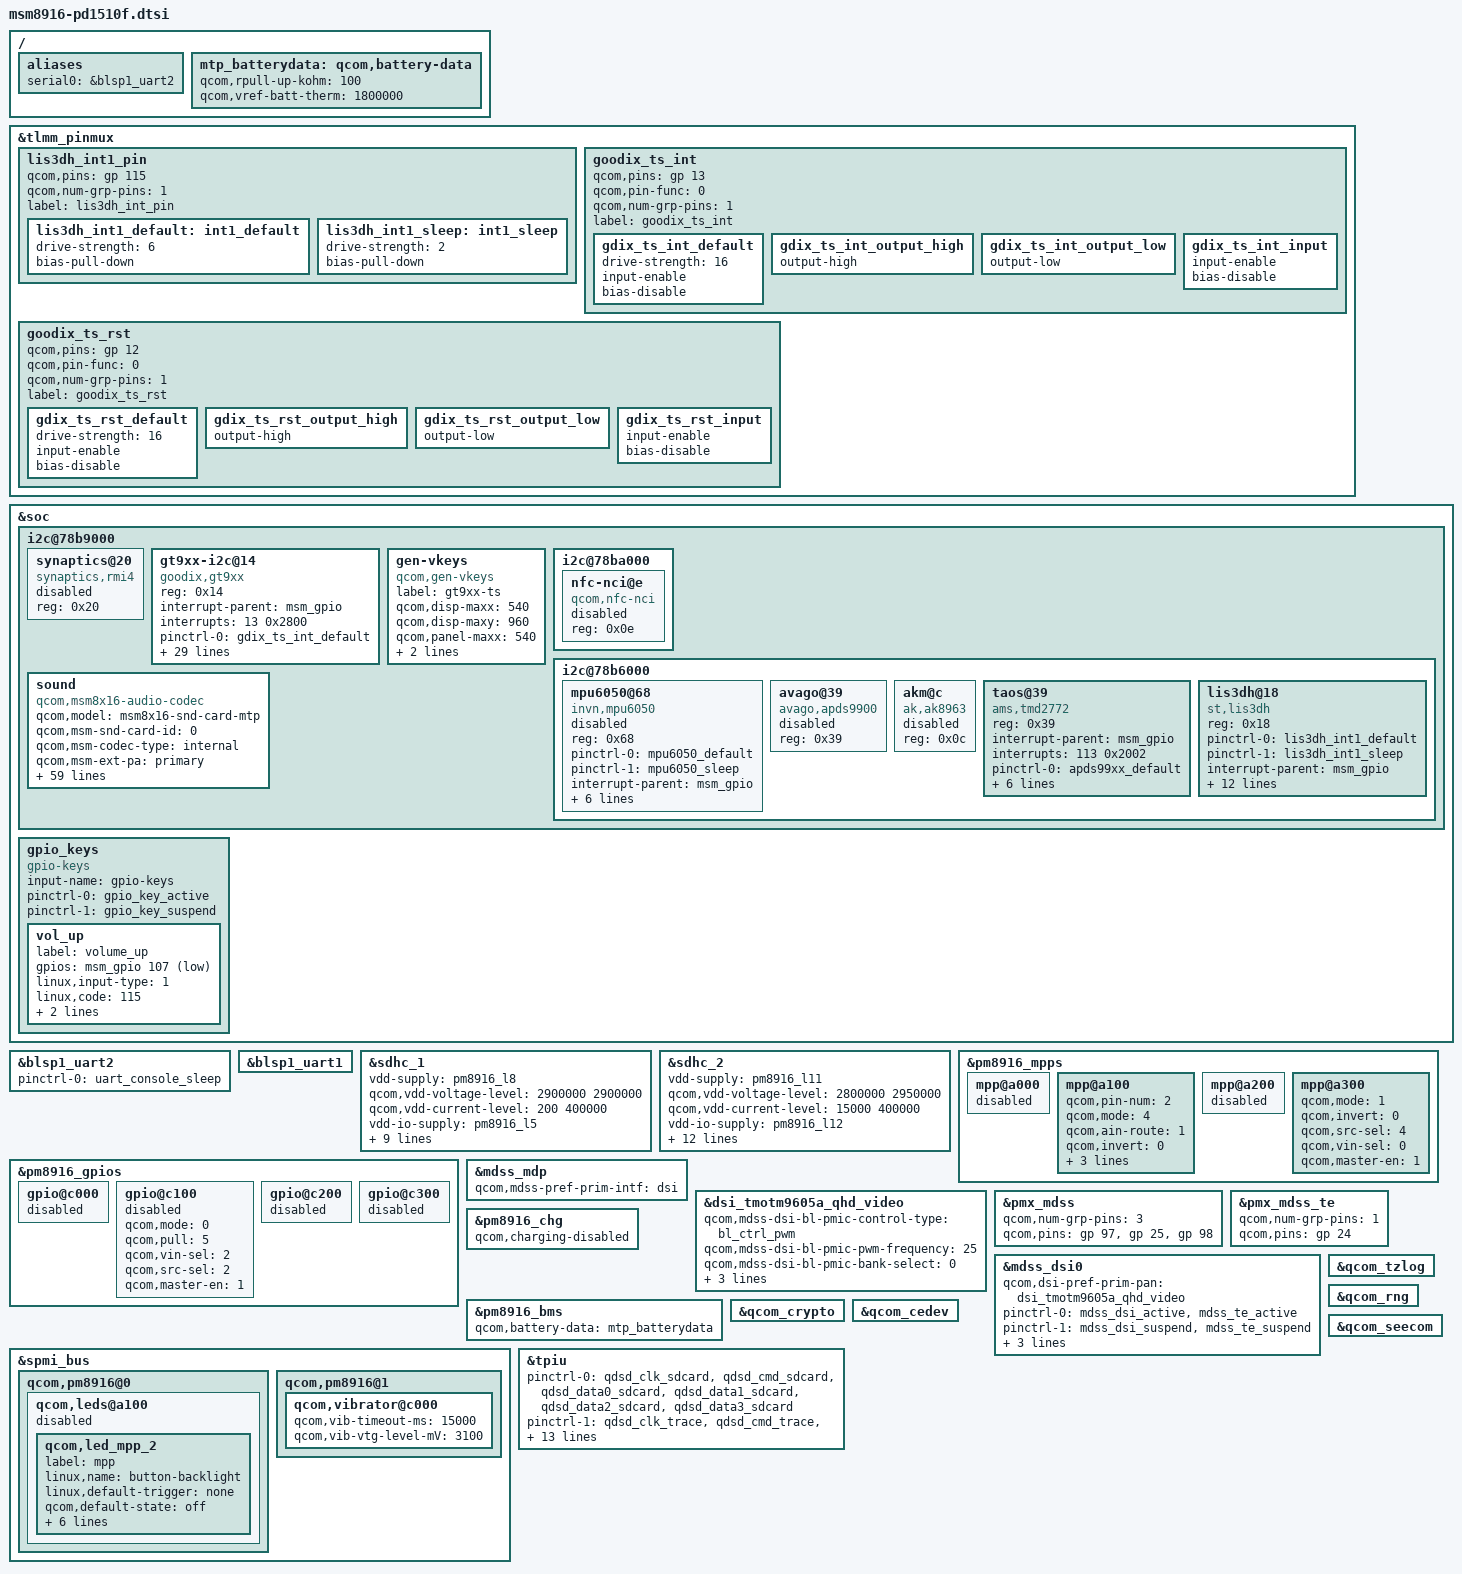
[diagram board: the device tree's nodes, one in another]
/* Copyright (c) 2020, The Linux Foundation. All rights reserved.
 *
 * This program is free software; you can redistribute it and/or modify
 * it under the terms of the GNU General Public License version 2 and
 * only version 2 as published by the Free Software Foundation.
 *
 * This program is distributed in the hope that it will be useful,
 * but WITHOUT ANY WARRANTY; without even the implied warranty of
 * MERCHANTABILITY or FITNESS FOR A PARTICULAR PURPOSE.  See the
 * GNU General Public License for more details.
 */

#include "msm8916.dtsi"
#include "msm8916-pinctrl.dtsi"
#include "msm8916-camera-pd1510f.dtsi"

/ {
	aliases {
		serial0 = &blsp1_uart2;
	};
};

&tlmm_pinmux {
	lis3dh_int1_pin {
		qcom,pins = <&gp 115>;
		qcom,num-grp-pins = <1>;
		label = "lis3dh_int_pin";

		lis3dh_int1_default: int1_default {
				drive-strength = <6>;
				bias-pull-down;
		};

		lis3dh_int1_sleep: int1_sleep {
				drive-strength = <2>;
				bias-pull-down;
		};
	};

	goodix_ts_int {
		qcom,pins = <&gp 13>;
		qcom,pin-func = <0>;
		qcom,num-grp-pins = <1>;
		label = "goodix_ts_int";

		gdix_ts_int_default: gdix_ts_int_default {
			drive-strength = <16>;
			input-enable;
			bias-disable;
		};

		gdix_ts_int_output_high: gdix_ts_int_output_high {
			output-high;
		};

		gdix_ts_int_output_low: gdix_ts_int_output_low {
			output-low;
		};

		gdix_ts_int_input: gdix_ts_int_input {
			input-enable;
			bias-disable;
		};
	};

	goodix_ts_rst {
		qcom,pins = <&gp 12>;
		qcom,pin-func = <0>;
		qcom,num-grp-pins = <1>;
		label = "goodix_ts_rst";

		gdix_ts_rst_default: gdix_ts_rst_default {
			drive-strength = <16>;
			input-enable;
			bias-disable;
		};

		gdix_ts_rst_output_high: gdix_ts_rst_output_high {
			output-high;
		};

		gdix_ts_rst_output_low: gdix_ts_rst_output_low {
			output-low;
		};

		gdix_ts_rst_input: gdix_ts_rst_input {
			input-enable;
			bias-disable;
		};
	};

};

&soc {
	i2c@78b9000 { /* BLSP1 QUP5 */
		synaptics@20 {
			compatible = "synaptics,rmi4";
			reg = <0x20>;
			status = "disabled";
	};

	gt9xx-i2c@14 {
			compatible = "goodix,gt9xx";
			reg = <0x14>;
			interrupt-parent = <&msm_gpio>;
			interrupts = <13 0x2800>;
			pinctrl-names = "gdix_ts_int_default",
				"gdix_ts_int_output_low",
				"gdix_ts_int_output_high",
				"gdix_ts_int_input",
				"gdix_ts_rst_default",
				"gdix_ts_rst_output_low",
				"gdix_ts_rst_output_high",
				"gdix_ts_rst_input";
			pinctrl-0 = <&gdix_ts_int_default>;
			pinctrl-1 = <&gdix_ts_int_output_low>;
			pinctrl-2 = <&gdix_ts_int_output_high>;
			pinctrl-3 = <&gdix_ts_int_input>;
			pinctrl-4 = <&gdix_ts_rst_default>;
			pinctrl-5 = <&gdix_ts_rst_output_low>;
			pinctrl-6 = <&gdix_ts_rst_output_high>;
			pinctrl-7 = <&gdix_ts_rst_input>;
			reset-gpios = <&msm_gpio 12 0x00>;
			irq-gpios = <&msm_gpio 13 0x2800>;
			irq-flags = <1>;
			vdd_ana-supply = <&pm8916_l16>;
			vcc_i2c-supply = <&pm8916_l6>;
			touchscreen-max-id = <11>;
			touchscreen-size-x = <540>;
			touchscreen-size-y = <960>;
			touchscreen-max-w = <512>;
			touchscreen-max-p = <512>;
			touchscreen-key-map = <158>, <102>, <139>; /*KEY_BACK=158，KEY_HOMEPAGE=102, KEY_MENU=139*/
			goodix,slide-wakeup = <1>;
			goodix,type-a-report = <0>;
			goodix,driver-send-cfg = <1>;
			goodix,resume-in-workqueue = <0>;
			goodix,int-sync = <1>;
			goodix,swap-x2y = <0>;
			goodix,esd-protect = <1>;
			goodix,auto-update = <0>;
			goodix,auto-update-cfg = <0>;
			goodix,power-off-sleep = <0>;
			goodix,pen-suppress-finger = <0>;
		};

	gen-vkeys {
		compatible = "qcom,gen-vkeys";
		label = "gt9xx-ts";
		qcom,disp-maxx = <540>;
		qcom,disp-maxy = <960>;
		qcom,panel-maxx = <540>;
		qcom,panel-maxy = <1030>;
		qcom,key-codes = <158 102 139>;
	};

	i2c@78ba000 { /* BLSP1 QUP6 */
		nfc-nci@e {
			compatible = "qcom,nfc-nci";
			reg = <0x0e>;
			status = "disabled";
		};
	};

	i2c@78b6000 { /* BLSP1 QUP2 */
		mpu6050@68 { /* Gyroscope and accelerometer sensor combo */
			compatible = "invn,mpu6050";
			reg = <0x68>;
			status = "disabled";
			pinctrl-names = "mpu_default","mpu_sleep";
			pinctrl-0 = <&mpu6050_default>;
			pinctrl-1 = <&mpu6050_sleep>;
			interrupt-parent = <&msm_gpio>;
			interrupts = <115 0x2>;
			vdd-supply = <&pm8916_l17>;
			vlogic-supply = <&pm8916_l16>;
			vi2c-supply = <&pm8916_l6>;
			invn,gpio-int = <&msm_gpio 115 0x2>;
			invn,place = "Portrait Down Back Side";
		};

		avago@39 { /* Ambient light and proximity sensor */
			compatible = "avago,apds9900";
			reg = <0x39>;
			status = "disabled";
		};

		akm@c {
			compatible = "ak,ak8963";
			reg = <0x0c>;
			status = "disabled";
		};

		taos@39 {
			compatible = "ams,tmd2772";
			reg = <0x39>;
			interrupt-parent = <&msm_gpio>;
			interrupts = <113 0x2002>;
			pinctrl-names = "tmd2772_default","tmd2772_sleep";
			pinctrl-0 = <&apds99xx_default>;
			pinctrl-1 = <&apds99xx_sleep>;
			vdd-supply = <&pm8916_l17>;
			vio-supply = <&pm8916_l6>;
			ams,irq-gpio = <&msm_gpio 113 0x2002>;
			ams,pul_cnt = <12>;
			ams,light-percent = <150>;
		};

		lis3dh@18 {
			compatible = "st,lis3dh";
			reg = <0x18>;
			pinctrl-names = "lis3dh_default","lis3dh_sleep";
			pinctrl-0 = <&lis3dh_int1_default>;
			pinctrl-1 = <&lis3dh_int1_sleep>;
			interrupt-parent = <&msm_gpio>;
			vdd-supply = <&pm8916_l17>;
			vddio-supply = <&pm8916_l6>;
			st,min-interval = <10>;
			st,init-interval = <200>;
			st,axis-map-x = <1>;
			st,axis-map-y = <0>;
			st,axis-map-z = <2>;
			st,g-range = <2>;
			st,gpio-int1 = <&msm_gpio 115 0x2002>;
			st,negate-x = <0>;
			st,negate-y = <0>;
			st,negate-z = <0>;
		};

	};

	sound {
		compatible = "qcom,msm8x16-audio-codec";
		qcom,model = "msm8x16-snd-card-mtp";
		qcom,msm-snd-card-id = <0>;
		qcom,msm-codec-type = "internal";
		qcom,msm-ext-pa = "primary";
		qcom,msm-mclk-freq = <9600000>;
		qcom,msm-mbhc-hphl-swh = <0>;
		qcom,msm-mbhc-gnd-swh = <0>;
		qcom,msm-micbias1-ext-cap;
		qcom,msm-hs-micbias-type = "external";
		qcom,audio-routing =
			"RX_BIAS", "MCLK",
			"SPK_RX_BIAS", "MCLK",
			"INT_LDO_H", "MCLK",
			"MIC BIAS External", "Handset Mic",
			"MIC BIAS Internal2", "Headset Mic",
			"MIC BIAS External", "Secondary Mic",
			"AMIC1", "MIC BIAS External",
			"AMIC2", "MIC BIAS Internal2",
			"AMIC3", "MIC BIAS External",
			"DMIC1", "MIC BIAS Internal1",
			"MIC BIAS Internal1", "Digital Mic1",
			"DMIC2", "MIC BIAS Internal1",
			"MIC BIAS Internal1", "Digital Mic2";
		pinctrl-names = "cdc_lines_act",
				"cdc_lines_sus",
				"cdc_lines_sec_ext_act",
				"cdc_lines_sec_ext_sus",
				"cross_conn_det_act",
				"cross_conn_det_sus";
		pinctrl-0 = <&cdc_pdm_lines_act>;
		pinctrl-1 = <&cdc_pdm_lines_sus>;
		pinctrl-2 = <&cdc_pdm_lines_act &cdc_ext_pa_act
						&cdc_ext_pa_ws_act>;
		pinctrl-3 = <&cdc_pdm_lines_sus &cdc_ext_pa_sus
						&cdc_ext_pa_ws_sus>;
		pinctrl-4 = <&cross_conn_det_act>;
		pinctrl-5 = <&cross_conn_det_sus>;
		qcom,cdc-us-euro-gpios = <&msm_gpio 120 0>;
		asoc-platform = <&pcm0>, <&pcm1>, <&voip>, <&voice>,
				<&loopback>, <&compress>, <&hostless>,
				<&afe>, <&lsm>, <&routing>, <&lpa>;
		asoc-platform-names = "msm-pcm-dsp.0", "msm-pcm-dsp.1",
				"msm-voip-dsp", "msm-pcm-voice", "msm-pcm-loopback",
				"msm-compress-dsp", "msm-pcm-hostless", "msm-pcm-afe",
				"msm-lsm-client", "msm-pcm-routing", "msm-pcm-lpa";
		asoc-cpu = <&dai_pri_auxpcm>, <&dai_hdmi>,
				<&dai_mi2s0>, <&dai_mi2s1>, <&dai_mi2s2>, <&dai_mi2s3>,
				<&sb_0_rx>, <&sb_0_tx>, <&sb_1_rx>, <&sb_1_tx>,
				<&sb_3_rx>, <&sb_3_tx>, <&sb_4_rx>, <&sb_4_tx>,
				<&bt_sco_rx>, <&bt_sco_tx>, <&bt_a2dp_rx>,
				<&int_fm_rx>, <&int_fm_tx>,
				<&afe_pcm_rx>, <&afe_pcm_tx>, <&afe_proxy_rx>, <&afe_proxy_tx>,
				<&incall_record_rx>, <&incall_record_tx>, <&incall_music_rx>,
				<&incall_music_2_rx>;
		asoc-cpu-names = "msm-dai-q6-auxpcm.1", "msm-dai-q6-hdmi.8",
				"msm-dai-q6-mi2s.0", "msm-dai-q6-mi2s.1",
				"msm-dai-q6-mi2s.2", "msm-dai-q6-mi2s.3",
				"msm-dai-q6-dev.16384", "msm-dai-q6-dev.16385",
				"msm-dai-q6-dev.16386", "msm-dai-q6-dev.16387",
				"msm-dai-q6-dev.16390", "msm-dai-q6-dev.16391",
				"msm-dai-q6-dev.16392", "msm-dai-q6-dev.16393",
				"msm-dai-q6-dev.12288", "msm-dai-q6-dev.12289",
				"msm-dai-q6-dev.12290", "msm-dai-q6-dev.12292",
				"msm-dai-q6-dev.12293",	"msm-dai-q6-dev.224",
				"msm-dai-q6-dev.225", "msm-dai-q6-dev.241",
				"msm-dai-q6-dev.240", "msm-dai-q6-dev.32771",
				"msm-dai-q6-dev.32772", "msm-dai-q6-dev.32773",
				"msm-dai-q6-dev.32770";
		asoc-codec = <&stub_codec>, <&pm8916_tombak_dig>;
		asoc-codec-names = "msm-stub-codec.1", "tombak_codec";
	};
   };

};

&blsp1_uart2 {
	status = "ok";
	pinctrl-names = "default";
	pinctrl-0 = <&uart_console_sleep>;
};

&soc {
	gpio_keys {
		compatible = "gpio-keys";
		input-name = "gpio-keys";
		pinctrl-names = "tlmm_gpio_key_active","tlmm_gpio_key_suspend";
		pinctrl-0 = <&gpio_key_active>;
		pinctrl-1 = <&gpio_key_suspend>;


		vol_up {
			label = "volume_up";
			gpios = <&msm_gpio 107 0x1>;
			linux,input-type = <1>;
			linux,code = <115>;
			gpio-key,wakeup;
			debounce-interval = <15>;
		};
	};
};

&blsp1_uart1 {
	status = "ok";
};

&sdhc_1 {
	vdd-supply = <&pm8916_l8>;
	qcom,vdd-voltage-level = <2900000 2900000>;
	qcom,vdd-current-level = <200 400000>;

	vdd-io-supply = <&pm8916_l5>;
	qcom,vdd-io-always-on;
	qcom,vdd-io-lpm-sup;
	qcom,vdd-io-voltage-level = <1800000 1800000>;
	qcom,vdd-io-current-level = <200 60000>;

	pinctrl-names = "active", "sleep";
	pinctrl-0 = <&sdc1_clk_on &sdc1_cmd_on &sdc1_data_on>;
	pinctrl-1 = <&sdc1_clk_off &sdc1_cmd_off &sdc1_data_off>;

	qcom,nonremovable;

	status = "ok";
};

&sdhc_2 {
	vdd-supply = <&pm8916_l11>;
	qcom,vdd-voltage-level = <2800000 2950000>;
	qcom,vdd-current-level = <15000 400000>;

	vdd-io-supply = <&pm8916_l12>;
	qcom,vdd-io-voltage-level = <1800000 2950000>;
	qcom,vdd-io-current-level = <200 50000>;

	pinctrl-names = "active", "sleep";
	pinctrl-0 = <&sdc2_clk_on &sdc2_cmd_on &sdc2_data_on &sdc2_cd_on>;
	pinctrl-1 = <&sdc2_clk_off &sdc2_cmd_off &sdc2_data_off &sdc2_cd_off>;

	#address-cells = <0>;
	interrupt-parent = <&sdhc_2>;
	interrupts = <0 1 2>;
	#interrupt-cells = <1>;
	interrupt-map-mask = <0xffffffff>;
	interrupt-map = <0 &intc 0 125 0
			1 &intc 0 221 0
			2 &msm_gpio 38 0>;
	interrupt-names = "hc_irq", "pwr_irq", "status_irq";
	cd-gpios = <&msm_gpio 38 0x1>;

	status = "ok";
};

&pm8916_mpps {
	mpp@a000 { /* MPP 1 */
		/* VDD_PX */
		status = "disabled";
	};

	mpp@a100 { /* MPP 2 */
		/* HR LED */
		qcom,pin-num = <2>;
		status = "ok";
		qcom,mode = <4>;
		qcom,ain-route = <1>;
		qcom,invert = <0>;
		qcom,output-type = <0>;
		qcom,src-sel = <0>;
		qcom,master-en = <1>;
	};

	mpp@a200 { /* MPP 3 */
		/* VREF DAC */
		status = "disabled";
	};

	mpp@a300 { /* MPP 4 */
		/* Backlight PWM */
		qcom,mode = <1>;		/* Digital output */
		qcom,invert = <0>;		/* Disable invert */
		qcom,src-sel = <4>;		/* DTEST1 */
		qcom,vin-sel = <0>;		/* VPH_PWR */
		qcom,master-en = <1>;		/* Enable MPP */
	};
};

&pm8916_gpios {
	gpio@c000 { /* GPIO 1 */
		/* Battery UICC Alarm */
		status = "disabled";
	};

	gpio@c100 { /* GPIO 2 */
		/* NFC_CLK_REQ */
		status = "disabled";
		qcom,mode = <0>; /* QPNP_PIN_MODE_DIG_IN */
		qcom,pull = <5>; /* QPNP_PIN_PULL_NO */
		qcom,vin-sel = <2>; /* QPNP_PIN_VIN2 */
		qcom,src-sel = <2>; /* QPNP_PIN_SEL_FUNC_1 */
		qcom,master-en = <1>;
	};

	gpio@c200 { /* GPIO 3 */
		/* External regulator control for WTR */
		status = "disabled";
	};

	gpio@c300 { /* GPIO 4 */
		/* External regulator control for APC */
		status = "disabled";
	};
};

#include "dsi-panel-tmotm9605a-qhd-video.dtsi"

&mdss_mdp {
	qcom,mdss-pref-prim-intf = "dsi";
};

&dsi_tmotm9605a_qhd_video {
	qcom,mdss-dsi-bl-pmic-control-type = "bl_ctrl_pwm";
	qcom,mdss-dsi-bl-pmic-pwm-frequency = <25>;
	qcom,mdss-dsi-bl-pmic-bank-select = <0>;
	qcom,mdss-dsi-pwm-gpio = <&pm8916_mpps 4 0>;
	qcom,mdss-dsi-pan-enable-dynamic-fps;
};

&pmx_mdss {
	qcom,num-grp-pins = <3>;
	qcom,pins = <&gp 97>, <&gp 25>, <&gp 98>;
};

&pmx_mdss_te {
	qcom,num-grp-pins = <1>;
	qcom,pins = <&gp 24>;
};

&mdss_dsi0 {
	qcom,dsi-pref-prim-pan = <&dsi_tmotm9605a_qhd_video>;
	pinctrl-names = "mdss_default", "mdss_sleep";
	pinctrl-0 = <&mdss_dsi_active &mdss_te_active>;
	pinctrl-1 = <&mdss_dsi_suspend &mdss_te_suspend>;

	qcom,platform-enable-gpio = <&msm_gpio 97 0>;
	qcom,platform-reset-gpio = <&msm_gpio 25 0>;
	qcom,platform-bklight-en-gpio = <&msm_gpio 98 0>;
};

&dsi_tmotm9605a_qhd_video {
       qcom,cont-splash-enabled;
};

&pm8916_chg {
	status = "ok";
	qcom,charging-disabled;
};

/ {
	mtp_batterydata: qcom,battery-data {
		qcom,rpull-up-kohm = <100>;
		qcom,vref-batt-therm = <1800000>;

		#include "batterydata-samsung-ds-4v35-2300mah.dtsi"
	};
};

&pm8916_bms {
	status = "ok";
	qcom,battery-data = <&mtp_batterydata>;
};

&spmi_bus {
	qcom,pm8916@0 {
		qcom,leds@a100 {
			status = "disabled";
			qcom,led_mpp_2 {
				label = "mpp";
				linux,name = "button-backlight";
				linux,default-trigger = "none";
				qcom,default-state = "off";
				qcom,max-current = <40>;
				qcom,current-setting = <5>;
				qcom,id = <6>;
				qcom,mode = "manual";
				qcom,source-sel = <1>;
				qcom,mode-ctrl = <0x60>;
			};
		};
	};
};

&qcom_tzlog {
	status = "okay";
};

&qcom_rng {
	status = "okay";
};

&qcom_crypto {
	status = "okay";
};

&qcom_cedev {
	status = "okay";
};

&qcom_seecom {
	status = "okay";
};

/* CoreSight */
&tpiu {
      pinctrl-names = "sdcard", "trace", "swduart",
		      "swdtrc", "jtag", "spmi";
       /* NIDnT */
      pinctrl-0 = <&qdsd_clk_sdcard &qdsd_cmd_sdcard
                  &qdsd_data0_sdcard &qdsd_data1_sdcard
                  &qdsd_data2_sdcard &qdsd_data3_sdcard>;
      pinctrl-1 = <&qdsd_clk_trace &qdsd_cmd_trace
                  &qdsd_data0_trace &qdsd_data1_trace
                  &qdsd_data2_trace &qdsd_data3_trace>;
      pinctrl-2 = <&qdsd_cmd_swduart &qdsd_data0_swduart
                  &qdsd_data1_swduart &qdsd_data2_swduart
                  &qdsd_data3_swduart>;
      pinctrl-3 = <&qdsd_clk_swdtrc &qdsd_cmd_swdtrc
                  &qdsd_data0_swdtrc &qdsd_data1_swdtrc
                  &qdsd_data2_swdtrc &qdsd_data3_swdtrc>;
      pinctrl-4 = <&qdsd_cmd_jtag &qdsd_data0_jtag
                  &qdsd_data1_jtag &qdsd_data2_jtag
                  &qdsd_data3_jtag>;
      pinctrl-5 = <&qdsd_clk_spmi &qdsd_cmd_spmi
                  &qdsd_data0_spmi &qdsd_data3_spmi>;
};

&spmi_bus {
	qcom,pm8916@1 {
		qcom,vibrator@c000 {
			status = "okay";
			qcom,vib-timeout-ms = <15000>;
			qcom,vib-vtg-level-mV = <3100>;
		};
	};
};
